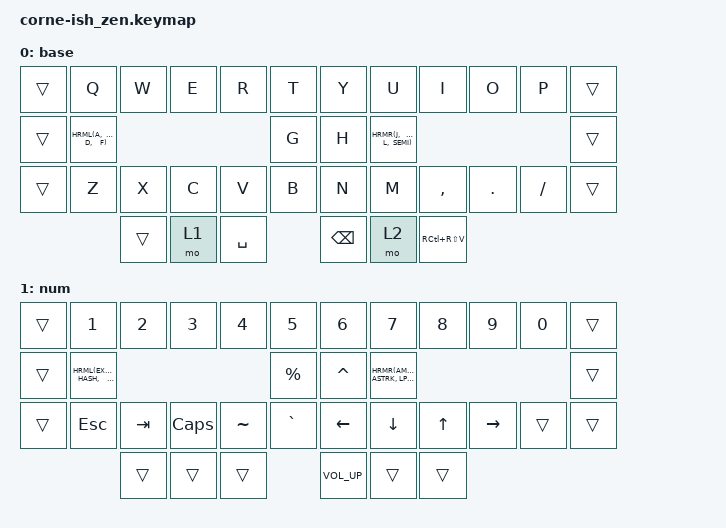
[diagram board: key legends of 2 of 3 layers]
// Copyright 2022 jack (@waffle87)
// SPDX-License-Identifier: MIT

#include <behaviors.dtsi>
#include <dt-bindings/zmk/keys.h>
#include <dt-bindings/zmk/bt.h>
#include "util.h"

/ {
  keymap {
    compatible = "zmk,keymap";
      base {
        bindings = <
          &trans &kp  Q &kp W &kp E &kp R  &kp T      &kp Y &kp  U &kp I     &kp O   &kp P    &trans
          &trans HRML(A,    S,    D,    F) &kp G      &kp H HRMR(J,    K,        L,  SEMI)    &trans
          &trans &kp  Z &kp X &kp C &kp V  &kp B      &kp N &kp  M &kp COMMA &kp DOT &kp FSLH &trans
                          &trans &mo 1 &kp SPACE      &kp BSPC &mo 2 &kp RC(RS(V))
        >;
      };
      num {
        bindings = <
					&trans &kp  N1   &kp N2  &kp N3   &kp N4    &kp N5         &kp N6    &kp  N7   &kp N8 &kp N9 &kp N0     &trans
          &trans HRML(EXCL,    AT,     HASH,    DLLR) &kp PRCNT      &kp CARET HRMR(AMPS,    ASTRK, LPAR,  RPAR)  &trans
          &trans &kp  ESC  &kp TAB &kp CAPS &kp TILDE &kp GRAVE      &kp LEFT  &kp  DOWN &kp UP &kp RIGHT  &trans &trans
                                            &trans &trans &trans     &kp C_VOL_UP &trans &trans
        >;
      };
      sym {
        bindings = <
          &trans &trans &trans &trans &trans &trans      &kp C_PREV &kp C_PLAY &kp C_NEXT &bt BT_CLR &bootloader &trans
          &trans &trans &trans &trans &trans &trans      &trans     &trans     &trans     &bt BT_PRV &bt BT_NXT  &trans
          &trans &kp F1 &kp F2 &kp F3 &kp F4 &kp F5      &kp F6     &kp F7     &kp F8     &kp F9     &kp F10     &trans
                        &trans &trans &kp C_VOL_DN       &trans &trans &trans
        >;
      };
  };

  behaviors {
    hm: homerow_mods {
        compatible = "zmk,behavior-hold-tap";
        label = "HOMEROW_MODS";
        #binding-cells = <2>;
        tapping-term-ms = <150>;
        quick_tap_ms = <0>;
        flavor = "tap-preferred";
        bindings = <&kp>, <&kp>;
    };
  };

  combos {
    compatible = "zmk,combos";
      COMBO(ENTR, &kp RET, 4 7)
      COMBO(QUOT, &kp SQT, 17 18)
      COMBO(DQUO, &kp DQT, 27 32)
      COMBO(LBRC, &kp LBRC, 3 4)
      COMBO(RBRC, &kp RBRC, 4 5)
      COMBO(LBKT, &kp LBKT, 6 7)
      COMBO(RBKT, &kp RBKT, 7 8)
      COMBO(BKSL, &kp BSLH, 3 8)
      COMBO(COLN, &kp COLON, 5 6)
      COMBO(PLUS, &kp PLUS, 14 21)
      COMBO(QUES, &kp QMARK, 28 31)
      COMBO(UNDS, &kp UNDER, 29 30)
      COMBO(MINS, &kp MINUS, 2 9)
      COMBO(EQAL, &kp EQUAL, 15 20)
      COMBO(CAPW, &caps_word, 16 19)
  };
};
